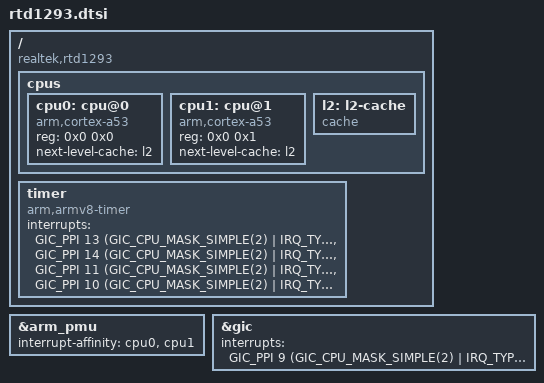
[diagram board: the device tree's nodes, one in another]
// SPDX-License-Identifier: (GPL-2.0-or-later OR BSD-2-Clause)
/*
 * Realtek RTD1293 SoC
 *
 * Copyright (c) 2017-2019 Andreas Färber
 */

#include "rtd129x.dtsi"

/ {
	compatible = "realtek,rtd1293";

	cpus {
		#address-cells = <2>;
		#size-cells = <0>;

		cpu0: cpu@0 {
			device_type = "cpu";
			compatible = "arm,cortex-a53";
			reg = <0x0 0x0>;
			next-level-cache = <&l2>;
		};

		cpu1: cpu@1 {
			device_type = "cpu";
			compatible = "arm,cortex-a53";
			reg = <0x0 0x1>;
			next-level-cache = <&l2>;
		};

		l2: l2-cache {
			compatible = "cache";
		};
	};

	timer {
		compatible = "arm,armv8-timer";
		interrupts = <GIC_PPI 13
			(GIC_CPU_MASK_SIMPLE(2) | IRQ_TYPE_LEVEL_LOW)>,
			     <GIC_PPI 14
			(GIC_CPU_MASK_SIMPLE(2) | IRQ_TYPE_LEVEL_LOW)>,
			     <GIC_PPI 11
			(GIC_CPU_MASK_SIMPLE(2) | IRQ_TYPE_LEVEL_LOW)>,
			     <GIC_PPI 10
			(GIC_CPU_MASK_SIMPLE(2) | IRQ_TYPE_LEVEL_LOW)>;
	};
};

&arm_pmu {
	interrupt-affinity = <&cpu0>, <&cpu1>;
};

&gic {
	interrupts = <GIC_PPI 9 (GIC_CPU_MASK_SIMPLE(2) | IRQ_TYPE_LEVEL_LOW)>;
};
